VERSION "0.0.01"

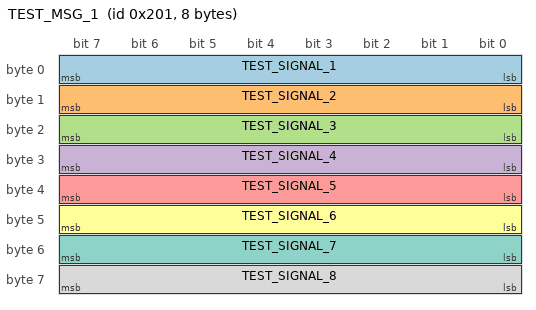
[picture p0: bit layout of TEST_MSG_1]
BO_ 513 TEST_MSG_1: 8 XXX
  SG_ TEST_SIGNAL_1 : 0|8@1+ (1,0) [0|255] ""  Vector__XXX
  SG_ TEST_SIGNAL_2 : 8|8@1+ (1,0) [0|255] ""  Vector__XXX
  SG_ TEST_SIGNAL_3 : 16|8@1+ (1,0) [0|255] ""  Vector__XXX
  SG_ TEST_SIGNAL_4 : 24|8@1+ (1,0) [0|255] ""  Vector__XXX
  SG_ TEST_SIGNAL_5 : 32|8@1+ (1,0) [0|255] ""  Vector__XXX
  SG_ TEST_SIGNAL_6 : 40|8@1+ (1,0) [0|255] ""  Vector__XXX
  SG_ TEST_SIGNAL_7 : 48|8@1+ (1,0) [0|255] ""  Vector__XXX
  SG_ TEST_SIGNAL_8 : 56|8@1+ (1,0) [0|255] ""  Vector__XXX
